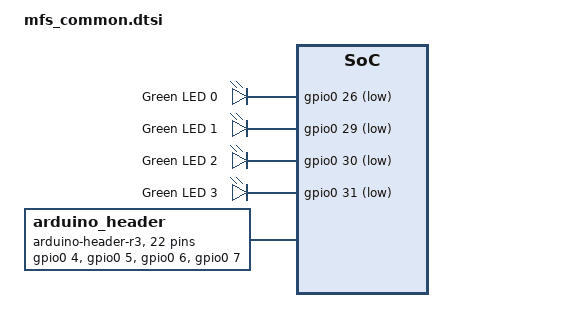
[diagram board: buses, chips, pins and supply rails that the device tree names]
/*
 * Copyright (c) 2020 Nordic Semiconductor ASA
 *
 * SPDX-License-Identifier: Apache-2.0
 */

/ {
	leds {
		compatible = "gpio-leds";
		led0: led_0 {
			gpios = <&gpio0 26 GPIO_ACTIVE_LOW>;
			label = "Green LED 0";
		};
		led1: led_1 {
			gpios = <&gpio0 29 GPIO_ACTIVE_LOW>;
			label = "Green LED 1";
		};
		led2: led_2 {
			gpios = <&gpio0 30 GPIO_ACTIVE_LOW>;
			label = "Green LED 2";
		};
		led3: led_3 {
			gpios = <&gpio0 31 GPIO_ACTIVE_LOW>;
			label = "Green LED 3";
		};
	};


	arduino_header: connector {
		compatible = "arduino-header-r3";
		#gpio-cells = <2>;
		gpio-map-mask = <0xffffffff 0xffffffc0>;
		gpio-map-pass-thru = <0 0x3f>;
		gpio-map = <0 0 &gpio0 4 0>,	/* A0 */
			   <1 0 &gpio0 5 0>,	/* A1 */
			   <2 0 &gpio0 6 0>,	/* A2 */
			   <3 0 &gpio0 7 0>,	/* A3 */
			   <4 0 &gpio0 25 0>,	/* A4 */
			   <5 0 &gpio0 26 0>,	/* A5 */
			   <6 0 &gpio1 0 0>,	/* D0 */
			   <7 0 &gpio1 1 0>,	/* D1 */
			   <8 0 &gpio1 4 0>,	/* D2 */
			   <9 0 &gpio1 5 0>,	/* D3 */
			   <10 0 &gpio1 6 0>,	/* D4 */
			   <11 0 &gpio1 7 0>,	/* D5 */
			   <12 0 &gpio1 8 0>,	/* D6 */
			   <13 0 &gpio1 9 0>,	/* D7 */
			   <14 0 &gpio1 10 0>,	/* D8 */
			   <15 0 &gpio1 11 0>,	/* D9 */
			   <16 0 &gpio1 12 0>,	/* D10 */
			   <17 0 &gpio1 13 0>,	/* D11 */
			   <18 0 &gpio1 14 0>,	/* D12 */
			   <19 0 &gpio1 15 0>,	/* D13 */
			   <20 0 &gpio1 2 0>,	/* D14 */
			   <21 0 &gpio1 3 0>;	/* D15 */
	};

	/* These aliases are provided for compatibility with samples */
	aliases {
		led0 = &led0;
		led1 = &led1;
		led2 = &led2;
		led3 = &led3;
		bootloader-led0 = &led0;
		mcuboot-led0 = &led0;
	};
};
